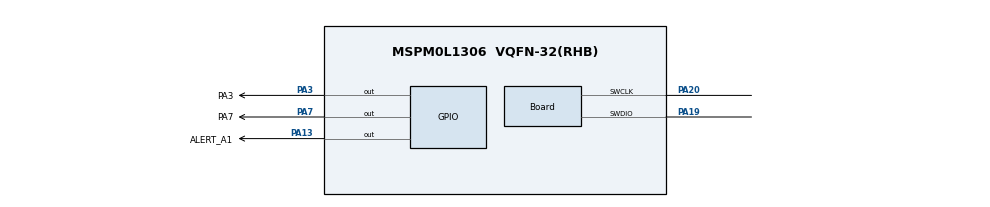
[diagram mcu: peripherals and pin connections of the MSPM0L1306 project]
//@cliArgs --device "MSPM0L130X" --package "VQFN-32(RHB)" --part "Default"
//@v2CliArgs --device "MSPM0L1306" --package "VQFN-32(RHB)"
// @cliArgs --board /ti/boards/LP_MSPM0L1306 --rtos nortos

/**
 * Import the modules used in this configuration.
 */
const Board         = scripting.addModule("/ti/driverlib/Board");
const COMP          = scripting.addModule("/ti/driverlib/COMP", {}, false);
const COMP1         = COMP.addInstance();
const COMPARE       = scripting.addModule("/ti/driverlib/COMPARE", {}, false);
const COMPARE1      = COMPARE.addInstance();
const GPIO          = scripting.addModule("/ti/driverlib/GPIO", {}, false);
const GPIO1         = GPIO.addInstance();
const GPIO2         = GPIO.addInstance();
const SYSCTL        = scripting.addModule("/ti/driverlib/SYSCTL");
const TIMER         = scripting.addModule("/ti/driverlib/TIMER", {}, false);
const TIMER1        = TIMER.addInstance();
const ProjectConfig = scripting.addModule("/ti/project_config/ProjectConfig");

/**
 * Write custom configuration values to the imported modules.
 */
Board.configureUnused             = true;
Board.genPeriphPinFile            = true;
Board.peripheral.$assign          = "DEBUGSS";
Board.peripheral.swclkPin.$assign = "PA20";
Board.peripheral.swdioPin.$assign = "PA19";
Board.genFileMod.$name            = "ti_driverlib_BoardPins0";

COMP1.$name                          = "COMP_0";
COMP1.vSource                        = "DL_COMP_REF_SOURCE_VDDA_DAC";
COMP1.controlSelect                  = "DL_COMP_DAC_CONTROL_SW";
COMP1.pubChanID                      = 1;
COMP1.enabledEvents                  = ["DL_COMP_EVENT_OUTPUT_EDGE"];
COMP1.hysteresis                     = "DL_COMP_HYSTERESIS_30";
COMP1.outputEnable                   = true;
COMP1.channelEnable                  = ["NEG"];
COMP1.setDACCode0                    = 0x80;
COMP1.peripheral.$assign             = "COMP0";
COMP1.peripheral.compPinOut.$assign  = "PA11";
COMP1.peripheral.compPinNeg0.$assign = "PA27";
COMP1.compPinOutConfig.$name         = "ti_driverlib_gpio_GPIOPinGeneric0";
COMP1.compPinNeg0Config.$name        = "ti_driverlib_gpio_GPIOPinGeneric3";

COMPARE1.$name              = "COMPARE_0";
COMPARE1.triggerSelect      = "Trigger";
COMPARE1.subscriberPort     = "FSUB0";
COMPARE1.subscriberChannel  = 1;
COMPARE1.timerClkSrc        = "MFCLK";
COMPARE1.timerPeriod        = 65000;
COMPARE1.peripheral.$assign = "TIMG4";

GPIO1.port                          = "PORTA";
GPIO1.$name                         = "GPIO";
GPIO1.associatedPins[0].$name       = "ALERT_A1";
GPIO1.associatedPins[0].assignedPin = "13";
GPIO1.associatedPins[0].pin.$assign = "PA13";

GPIO2.$name                          = "DEBUG";
GPIO2.associatedPins.create(2);
GPIO2.associatedPins[0].$name        = "PA3";
GPIO2.associatedPins[0].assignedPort = "PORTA";
GPIO2.associatedPins[0].pin.$assign  = "PA3";
GPIO2.associatedPins[1].$name        = "PA7";
GPIO2.associatedPins[1].assignedPort = "PORTA";
GPIO2.associatedPins[1].pin.$assign  = "PA7";

SYSCTL.MFCLKEn            = true;
SYSCTL.peripheral.$assign = "SYSCTL";

TIMER1.timerClkSrc        = "LFCLK";
TIMER1.timerMode          = "PERIODIC";
TIMER1.interrupts         = ["ZERO"];
TIMER1.$name              = "PERIOD_TIMER";
TIMER1.timerPeriod        = "500ms";
TIMER1.peripheral.$assign = "TIMG0";

ProjectConfig.deviceSpin = "MSPM0L1306";
scripting.suppress("Migrating requires going through the Switch Board or Device menu in the Device View section\\.", ProjectConfig, "deviceSpin");
